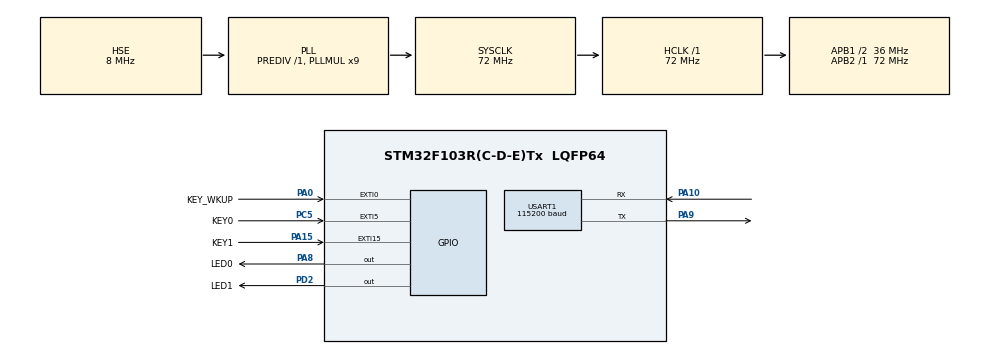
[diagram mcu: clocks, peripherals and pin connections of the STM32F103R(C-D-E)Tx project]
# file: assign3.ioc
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Dma.MEMTOMEM.1.Direction=DMA_MEMORY_TO_MEMORY
Dma.MEMTOMEM.1.Instance=DMA1_Channel6
Dma.MEMTOMEM.1.MemDataAlignment=DMA_MDATAALIGN_HALFWORD
Dma.MEMTOMEM.1.MemInc=DMA_MINC_ENABLE
Dma.MEMTOMEM.1.Mode=DMA_NORMAL
Dma.MEMTOMEM.1.PeriphDataAlignment=DMA_PDATAALIGN_HALFWORD
Dma.MEMTOMEM.1.PeriphInc=DMA_PINC_ENABLE
Dma.MEMTOMEM.1.Priority=DMA_PRIORITY_LOW
Dma.Request0=USART1_RX
Dma.Request1=MEMTOMEM
Dma.USART1_RX.0.Direction=DMA_PERIPH_TO_MEMORY
Dma.USART1_RX.0.Instance=DMA1_Channel5
Dma.USART1_RX.0.MemDataAlignment=DMA_MDATAALIGN_BYTE
Dma.USART1_RX.0.MemInc=DMA_MINC_ENABLE
Dma.USART1_RX.0.Mode=DMA_NORMAL
Dma.USART1_RX.0.PeriphDataAlignment=DMA_PDATAALIGN_BYTE
Dma.USART1_RX.0.PeriphInc=DMA_PINC_DISABLE
Dma.USART1_RX.0.Priority=DMA_PRIORITY_MEDIUM
Mcu.Family=STM32F1
Mcu.Name=STM32F103R(C-D-E)Tx
Mcu.Package=LQFP64
NVIC.DMA1_Channel5_IRQn=true\:1\:2\:true\:false\:true\:false\:true\:true
NVIC.DMA1_Channel6_IRQn=true\:1\:1\:true\:false\:true\:true\:true\:true
NVIC.EXTI0_IRQn=true\:2\:0\:true\:false\:true\:true\:true\:true
NVIC.EXTI15_10_IRQn=true\:2\:2\:true\:false\:true\:true\:true\:true
NVIC.EXTI9_5_IRQn=true\:2\:1\:true\:false\:true\:true\:true\:true
NVIC.PriorityGroup=NVIC_PRIORITYGROUP_2
NVIC.TIM6_IRQn=true\:1\:3\:true\:false\:true\:true\:true\:true
NVIC.USART1_IRQn=true\:1\:0\:true\:false\:true\:true\:true\:true
PA0-WKUP.GPIO_Label=KEY_WKUP
PA0-WKUP.GPIO_PuPd=GPIO_PULLDOWN
PA0-WKUP.Signal=GPXTI0
PA10.Mode=Asynchronous
PA10.Signal=USART1_RX
PA13.Mode=Serial_Wire
PA13.Signal=SYS_JTMS-SWDIO
PA14.Mode=Serial_Wire
PA14.Signal=SYS_JTCK-SWCLK
PA15.GPIO_Label=KEY1
PA15.GPIO_PuPd=GPIO_PULLUP
PA15.Signal=GPXTI15
PA8.GPIO_Label=LED0
PA8.Signal=GPIO_Output
PA9.Mode=Asynchronous
PA9.Signal=USART1_TX
PC5.GPIO_Label=KEY0
PC5.GPIO_PuPd=GPIO_PULLUP
PC5.Signal=GPXTI5
PD0-OSC_IN.Mode=HSE-External-Oscillator
PD0-OSC_IN.Signal=RCC_OSC_IN
PD1-OSC_OUT.Mode=HSE-External-Oscillator
PD1-OSC_OUT.Signal=RCC_OSC_OUT
PD2.GPIO_Label=LED1
PD2.Signal=GPIO_Output
ProjectManager.HeapSize=0x400
ProjectManager.StackSize=0x400
ProjectManager.TargetToolchain=CMake
RCC.AHBFreq_Value=72000000
RCC.APB1CLKDivider=RCC_HCLK_DIV2
RCC.APB1Freq_Value=36000000
RCC.APB1TimFreq_Value=72000000
RCC.APB2Freq_Value=72000000
RCC.APB2TimFreq_Value=72000000
RCC.HCLKFreq_Value=72000000
RCC.PLLMUL=RCC_PLL_MUL9
RCC.PLLSourceVirtual=RCC_PLLSOURCE_HSE
RCC.SYSCLKFreq_VALUE=72000000
RCC.SYSCLKSource=RCC_SYSCLKSOURCE_PLLCLK
RCC.USBFreq_Value=72000000
TIM6.AutoReloadPreload=TIM_AUTORELOAD_PRELOAD_DISABLE
TIM6.Period=200
TIM6.Prescaler=1800
USART1.BaudRate=115200
USART1.VirtualMode=VM_ASYNC
VP_TIM6_VS_ClockSourceINT.Mode=Enable_Timer
board=custom

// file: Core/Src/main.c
/* USER CODE BEGIN Header */
/**
 ******************************************************************************
 * @file           : main.c
 * @brief          : Main program body
 ******************************************************************************
 * @attention
 *
 * Copyright (c) 2024 STMicroelectronics.
 * All rights reserved.
 *
 * This software is licensed under terms that can be found in the LICENSE file
 * in the root directory of this software component.
 * If no LICENSE file comes with this software, it is provided AS-IS.
 *
 ******************************************************************************
 */
/* USER CODE END Header */
#include "main.h"

#include <stdio.h>

#include "dma.h"
#include "gpio.h"
#include "tim.h"
#include "usart.h"

/* USER CODE BEGIN Includes */
#include "lcd.h"
/* USER CODE END Includes */

/* USER CODE BEGIN PV */
USARTRecvBuffer USART1Buffer = {{0}, {0}, 0, USART_RECV_LEN};
extern DMA_HandleTypeDef hdma_usart1_rx;
/* USER CODE END PV */

void SystemClock_Config(void);

int main(void) {

  /* MCU Configuration--------------------------------------------------------*/

  /* Reset of all peripherals, Initializes the Flash interface and the Systick. */
  HAL_Init();

  /* Configure the system clock */
  SystemClock_Config();

  /* Initialize all configured peripherals */
  MX_GPIO_Init();
  MX_DMA_Init();
  MX_USART1_UART_Init();
  MX_TIM6_Init();
  HAL_TIM_Base_Start_IT(&htim6);
  /* USER CODE BEGIN 2 */
  HAL_UARTEx_ReceiveToIdle_DMA(&huart1, USART1Buffer.curBuffer, sizeof(USART1Buffer.curBuffer));
  __HAL_DMA_DISABLE_IT(&hdma_usart1_rx, DMA_IT_HT);
  LCD_Init();
  /* USER CODE END 2 */

  /* Infinite loop */
  uint8_t recvMsg[USART_RECV_BUFLEN] = {0};
  uint16_t pointColor = 0;
  uint8_t px=0, py=0;
  LCD_Clear(WHITE);
  BACK_COLOR = WHITE;
  POINT_COLOR = BLACK;
  while (1) {

    /* USER CODE BEGIN 3 */
    if (USART1Buffer.rxlen <= FRAME_LEN) {
      for (uint8_t i = 0; i < 20; i++) {
        px=i * 60;
        for (uint8_t j = 0; j < 60; j++) {
          pointColor = ((uint16_t)USART1Buffer.uBuffer[px + j] << 8) | (USART1Buffer.uBuffer[py + j + 1]);
          LCD_Fast_DrawPoint(i, j, pointColor);
        }
      }
    }
  }
  /* USER CODE END 3 */
}

void SystemClock_Config(void) {
  RCC_OscInitTypeDef RCC_OscInitStruct = {0};
  RCC_ClkInitTypeDef RCC_ClkInitStruct = {0};

  /** Initializes the RCC Oscillators according to the specified parameters
   * in the RCC_OscInitTypeDef structure.
   */
  RCC_OscInitStruct.OscillatorType = RCC_OSCILLATORTYPE_HSE;
  RCC_OscInitStruct.HSEState = RCC_HSE_ON;
  RCC_OscInitStruct.HSEPredivValue = RCC_HSE_PREDIV_DIV1;
  RCC_OscInitStruct.HSIState = RCC_HSI_ON;
  RCC_OscInitStruct.PLL.PLLState = RCC_PLL_ON;
  RCC_OscInitStruct.PLL.PLLSource = RCC_PLLSOURCE_HSE;
  RCC_OscInitStruct.PLL.PLLMUL = RCC_PLL_MUL9;
  if (HAL_RCC_OscConfig(&RCC_OscInitStruct) != HAL_OK) {
    Error_Handler();
  }

  /** Initializes the CPU, AHB and APB buses clocks
   */
  RCC_ClkInitStruct.ClockType = RCC_CLOCKTYPE_HCLK | RCC_CLOCKTYPE_SYSCLK | RCC_CLOCKTYPE_PCLK1 | RCC_CLOCKTYPE_PCLK2;
  RCC_ClkInitStruct.SYSCLKSource = RCC_SYSCLKSOURCE_PLLCLK;
  RCC_ClkInitStruct.AHBCLKDivider = RCC_SYSCLK_DIV1;
  RCC_ClkInitStruct.APB1CLKDivider = RCC_HCLK_DIV2;
  RCC_ClkInitStruct.APB2CLKDivider = RCC_HCLK_DIV1;

  if (HAL_RCC_ClockConfig(&RCC_ClkInitStruct, FLASH_LATENCY_2) != HAL_OK) {
    Error_Handler();
  }
}

void Error_Handler(void) {
  __disable_irq();
  while (1) {
  }
}
